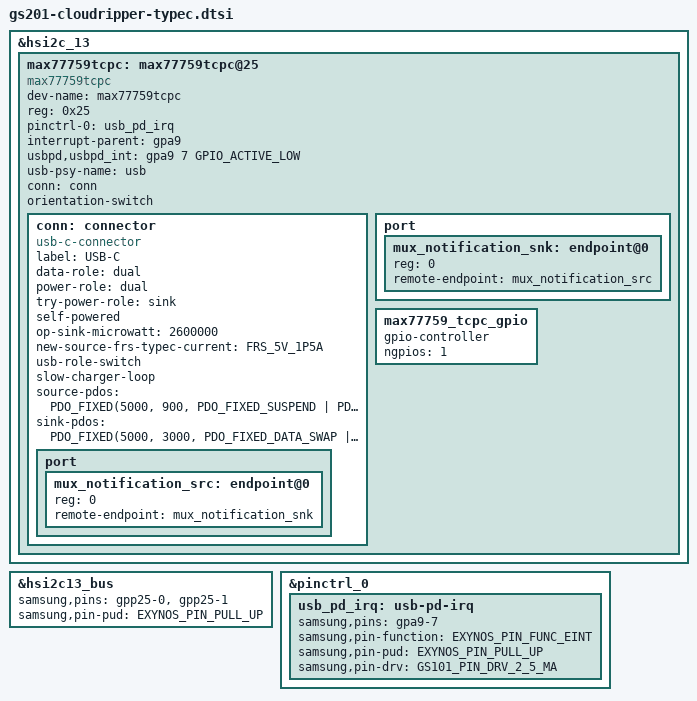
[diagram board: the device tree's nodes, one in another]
// SPDX-License-Identifier: GPL-2.0-only
/*
 * Copyright (C) 2021, Google LLC
 *
 * Cloudripper Type-C device tree
 */
#include <dt-bindings/usb/pd.h>
#include <dt-bindings/gpio/gpio.h>
#include <dt-bindings/pinctrl/samsung.h>

&hsi2c_13{
	#address-cells = <1>;
	#size-cells = <0>;
	status = "okay";

	max77759tcpc: max77759tcpc@25 {
		status = "okay";
		dev-name = "max77759tcpc";
		compatible = "max77759tcpc";
		reg = <0x25>;
		pinctrl-names = "default";
		pinctrl-0 = <&usb_pd_irq>;
		interrupt-parent = <&gpa9>;
		usbpd,usbpd_int = <&gpa9 7 GPIO_ACTIVE_LOW>;
		usb-psy-name = "usb";
		/* Enable when BMS is up */
		//chg-psy-name = "gcpm";
		//in-switch-gpio = <&max20339_gpio 4 GPIO_ACTIVE_HIGH>;
		//max20339,ovp = <&max20339_ovp>;
		conn = <&conn>;
		orientation-switch;

		conn: connector {
			compatible = "usb-c-connector";
			label = "USB-C";
			data-role = "dual";
			power-role = "dual";
			try-power-role = "sink";
			self-powered;
			op-sink-microwatt = <2600000>;
			new-source-frs-typec-current = <FRS_5V_1P5A>;
			usb-role-switch;
			slow-charger-loop;
			/*
			 * b/174044466: Extboost can only do ~1A.
			 * However, max77759 operating in reverse boost
			 * mode (0xA) can do till 1.5A.
			 * Since extboost is the primary path, set this
			 * to 900mA.
			 */
			source-pdos = <PDO_FIXED(5000, 900,
						 PDO_FIXED_SUSPEND |
						 PDO_FIXED_USB_COMM |
						 PDO_FIXED_DATA_SWAP |
						 PDO_FIXED_DUAL_ROLE)>;
			sink-pdos = <PDO_FIXED(5000, 3000,
					       PDO_FIXED_DATA_SWAP |
					       PDO_FIXED_USB_COMM |
					       PDO_FIXED_HIGHER_CAP |
					       PDO_FIXED_DUAL_ROLE)
				     PDO_FIXED(9000, 2200, 0)
				     PDO_PPS_APDO(5000, 11000, 3000)>;
			port {
				#address-cells = <1>;
				#size-cells = <0>;
				mux_notification_src: endpoint@0 {
					reg = <0>;
					remote-endpoint = <&mux_notification_snk>;
				};

			};
		};

		port {
			#address-cells = <1>;
			#size-cells = <0>;

			mux_notification_snk: endpoint@0 {
				reg = <0>;
				remote-endpoint = <&mux_notification_src>;
			};
		};

		/* EXT_BST_EN exposed as GPIO */
		max77759_tcpc_gpio: max77759_tcpc_gpio {
			gpio-controller;
			#gpio-cells = <2>;
			ngpios = <1>;
		};
	};
};

&hsi2c13_bus {
	samsung,pins = "gpp25-0", "gpp25-1";
	samsung,pin-pud = <EXYNOS_PIN_PULL_UP>;
};

&pinctrl_0 {
	usb_pd_irq: usb-pd-irq {
		samsung,pins = "gpa9-7";
		samsung,pin-function = <EXYNOS_PIN_FUNC_EINT>;
		samsung,pin-pud = <EXYNOS_PIN_PULL_UP>;
		samsung,pin-drv = <GS101_PIN_DRV_2_5_MA>;
	};
};
